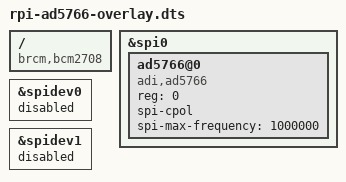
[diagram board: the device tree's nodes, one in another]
// SPDX-License-Identifier: GPL-2.0
/dts-v1/;
/plugin/;

/ {
	compatible = "brcm,bcm2708", "brcm,bcm2837";
};

&spi0 {
	#address-cells = <1>;
	#size-cells = <0>;
	status = "okay";

	ad5766@0{
		compatible = "adi,ad5766";
		reg = <0>;
		spi-cpol;
		spi-max-frequency = <1000000>;
	};
};

&spidev0 {
	status = "disabled";
};

&spidev1 {
	status = "disabled";
};
